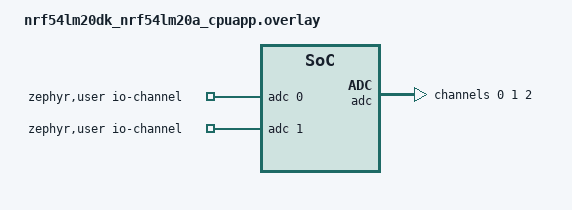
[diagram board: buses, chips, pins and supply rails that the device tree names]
/ {
	zephyr,user {
		io-channels = <&adc 0>, <&adc 1>;
	};
};

&adc {
	#address-cells = <1>;
	#size-cells = <0>;
	status = "okay";
	channel@0 {
		reg = <0>;
		zephyr,gain = "ADC_GAIN_1_4";
		zephyr,reference = "ADC_REF_INTERNAL";
		zephyr,acquisition-time = <ADC_ACQ_TIME_DEFAULT>;
		zephyr,input-positive = <NRF_SAADC_AIN6>; /* P1.04 */
		zephyr,resolution = <14>;
	};
	channel@1 {
		reg = <1>;
		zephyr,gain = "ADC_GAIN_1_4";
		zephyr,reference = "ADC_REF_INTERNAL";
		zephyr,acquisition-time = <ADC_ACQ_TIME_DEFAULT>;
		zephyr,input-positive = <NRF_SAADC_AIN7>; /* P1.03 */
		zephyr,resolution = <14>;
	};
	channel@2 {
		reg = <2>;
		zephyr,gain = "ADC_GAIN_1_4";
		zephyr,reference = "ADC_REF_INTERNAL";
		zephyr,acquisition-time = <ADC_ACQ_TIME_DEFAULT>;
		zephyr,input-positive = <NRF_SAADC_AIN4>; /* P1.03 */
		zephyr,resolution = <14>;
	};
};

